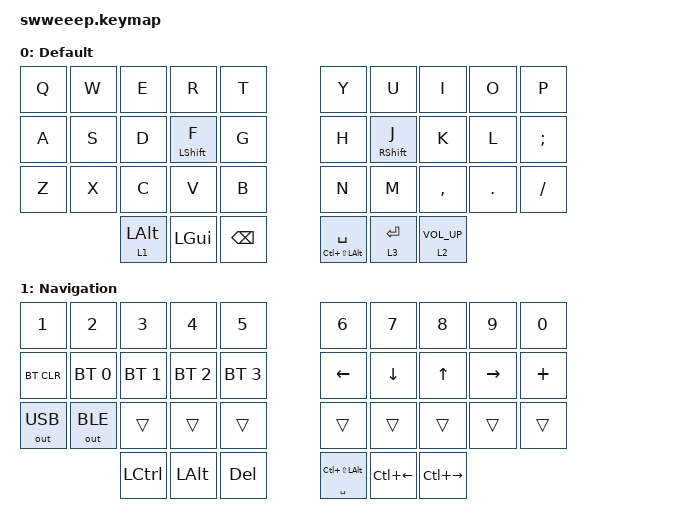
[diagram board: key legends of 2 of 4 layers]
#include <behaviors.dtsi>
#include <dt-bindings/zmk/keys.h>
#include <dt-bindings/zmk/bt.h>
#include <dt-bindings/zmk/outputs.h>

#define DEFAULT 0
#define NAV     1
#define SYM     2
#define SIN     3

&caps_word {
    continue-list = <UNDERSCORE MINUS>;
};

/ {
    behaviors {
        q_tab: q_tab {
            compatible = "zmk,behavior-mod-morph";
            label = "q_tab";
            #binding-cells = <0>;
            bindings = <&kp Q>, <&kp TAB>;
            mods = <(MOD_LGUI|MOD_RGUI)>;
            keep-mods = <(MOD_LGUI)>;

        };
    };
};

/ {
    combos {
        compatible = "zmk,combos";
        combo_undo {
            timeout-ms = <50>;
            key-positions = <20 21>;
            bindings = <&kp LC(Z)>;
        };
        combo_q {
            timeout-ms = <50>;
            key-positions = <21 22>;
            bindings = <&kp Q>;
        };
        combo_semicolon {
            timeout-ms = <50>;
            key-positions = <27 28>;
            bindings = <&kp SEMI>;
        };
    };
};

/ {

    behaviors {
        hm: layer_mods {
            compatible = "zmk,behavior-hold-tap";
            label = "LAYER_MODS";
            #binding-cells = <2>;
            tapping-term-ms = <200>;
            quick_tap_ms = <0>;
            flavor = "balanced";
            bindings = <&kp>, <&kp>;
        };
        hs: homerow_shift {
            compatible = "zmk,behavior-hold-tap";
            label = "HOMEROW_SHIFT";
            #binding-cells = <2>;
            tapping-term-ms = <250>;
            quick_tap_ms = <0>;
            flavor = "tap-preferred";
            bindings = <&kp>, <&kp>;
        };
    };


    keymap {
        compatible = "zmk,keymap";

        default_layer {
            label = "Default";

            bindings = <
    &kp Q        &kp W        &kp E       &kp R         &kp T          &kp Y                  &kp U            &kp I       &kp O         &kp P
    &kp A        &kp S        &kp D       &hs LSHIFT F  &kp G          &kp H                  &hs RSHIFT J     &kp K       &kp L         &kp SEMI
    &kp Z        &kp X        &kp C       &kp V         &kp B          &kp N                  &kp M            &kp COMMA   &kp DOT       &kp FSLH
                        &lt 1 LALT    &kp LGUI  &kp BACKSPACE          &mt LC(LS(LALT)) SPACE &lt 3 ENTER      &lt 2 C_VOL_UP
            >;
        };

        nav_layer {
            label = "Navigation";

            bindings = <
 &kp N1       &kp N2       &kp N3      &kp N4        &kp N5                            &kp N6          &kp N7           &kp N8        &kp N9      &kp N0
 &bt BT_CLR    &bt BT_SEL 0 &bt BT_SEL 1 &bt BT_SEL 2 &bt BT_SEL 3                 &kp LEFT        &kp DOWN         &kp UP        &kp RIGHT   &kp PLUS
 &out OUT_USB  &out OUT_BLE       &trans      &trans        &trans       &trans                   &trans  &trans &trans &trans
                                  &kp LCTL  &kp LALT  &kp DELETE         &mt SPACE LC(LS(LALT))   &kp LC(LEFT)    &kp LC(RIGHT)
               >;
        };

        sym_layer {
            label = "Symbols";

            bindings = <
    &kp EXCL &kp AT &kp HASH &kp DOLLAR &kp PRCNT                                      &kp CARET &kp AMPS  &kp KP_MULTIPLY &kp LPAR  &kp RPAR
    &bt BT_CLR    &bt BT_SEL 0 &bt BT_SEL 1 &bt BT_SEL 2 &bt BT_SEL 3                  &kp LEFT  &kp DOWN  &kp UP        &kp RIGHT   &kp PLUS
    &out OUT_USB  &out OUT_BLE       &trans      &trans        &trans                  &trans &trans  &trans &trans
                                    &trans        &kp LALT      &kp TAB        &kp LC(LEFT)   &kp LC(UP)    &kp LC(RIGHT)
                >;
        };
        sin_layer {
            label = "sinners";

            bindings = <
    &gresc  &kp AT &kp HASH &kp DOLLAR &kp PRCNT                                      &kp CARET &kp AMPS  &kp KP_MULTIPLY &kp LPAR  &kp MINUS
    &kp TAB &trans &trans   &trans     &trans                  &kp LEFT  &kp DOWN  &kp UP        &kp RIGHT   &kp EQUAL
    &trans  &trans &trans   &trans     &trans                  &trans &trans  &trans &kp SINGLE_QUOTE
                                    &trans        &kp LALT      &kp TAB        &kp LC(LEFT)   &kp LC(UP)    &kp LC(RIGHT)
                >;
        };
    };
};
